AUTOSAR XML (schema 4-2-1)
package /ComponentTypes
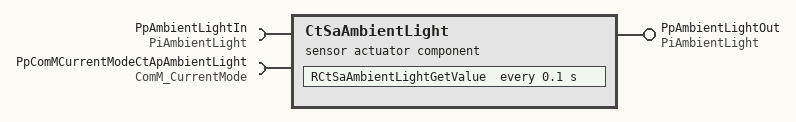
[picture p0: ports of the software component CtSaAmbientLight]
  sensor actuator sw component type CtSaAmbientLight
    provide port PpAmbientLightOut: nonqueued-sender-com-spec{data-element=DeAmbientLight, init-value=0}, provided-interface=PiAmbientLight
    require port PpAmbientLightIn: nonqueued-receiver-com-spec{data-element=DeAmbientLight, filter=data-filter-type=ALWAYS, init-value=constant-reference=CDarkLight}, required-interface=PiAmbientLight
    require port PpComMCurrentModeCtApAmbientLight: required-interface=ComM_CurrentMode
    behavior CtSaAmbientLight_InternalBehavior
      timing event TMT_RCtSaAmbientLightGetValue: start-on-event=RCtSaAmbientLightGetValue, period=0.1
      runnable RCtSaAmbientLightGetValue
        data-receive-point-by-arguments:
          access REC_PpAmbientLightIn_DeAmbientLight: accessed-variable=PpAmbientLightIn.DeAmbientLight
        data-send-points:
          access SEND_PpAmbientLightOut_DeAmbientLight: accessed-variable=PpAmbientLightOut.DeAmbientLight
  swc implementation CtSaAmbientLight_Implementation: behavior=CtSaAmbientLight_InternalBehavior
    code-descriptors:
      code Default: artifact-descriptors=autosar-engineering-object={short-label=Default, category=SWSRC}
